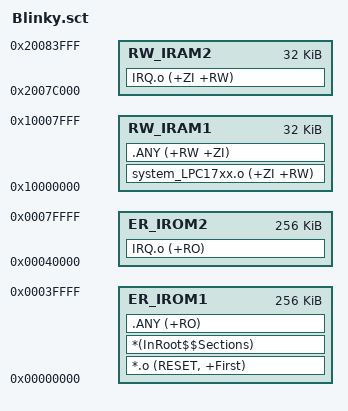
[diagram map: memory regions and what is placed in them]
; *************************************************************
; *** Scatter-Loading Description File generated by uVision ***
; *************************************************************

LR_IROM1 0x00000000 0x00040000  {    ; load region size_region
  ER_IROM1 0x00000000 0x00040000  {  ; load address = execution address
   *.o (RESET, +First)
   *(InRoot$$Sections)
   .ANY (+RO)
  }
  RW_IRAM1 0x10000000 0x00008000  {  ; RW data
    system_LPC17xx.o (+ZI +RW)
   .ANY (+RW +ZI)
  }
  RW_IRAM2 0x2007C000 0x00008000  {
    IRQ.o (+ZI +RW)
  }
}

LR_IROM2 0x00040000 0x00040000  {
  ER_IROM2 0x00040000 0x00040000  {  ; load address = execution address
    IRQ.o (+RO)
  }
}
